# MK20D5 register map
File version: 1.6
Registers are 8-bit, read-write, reset 0x0 unless marked. A register's access mark holds for its fields unless they carry their own. Offsets are from the block's base; [hi:lo] are bit positions; lines under a group give offsets from that group.

## SystemControl — System Control Registers
Base 0xE000E000; register names take the prefix SCB_
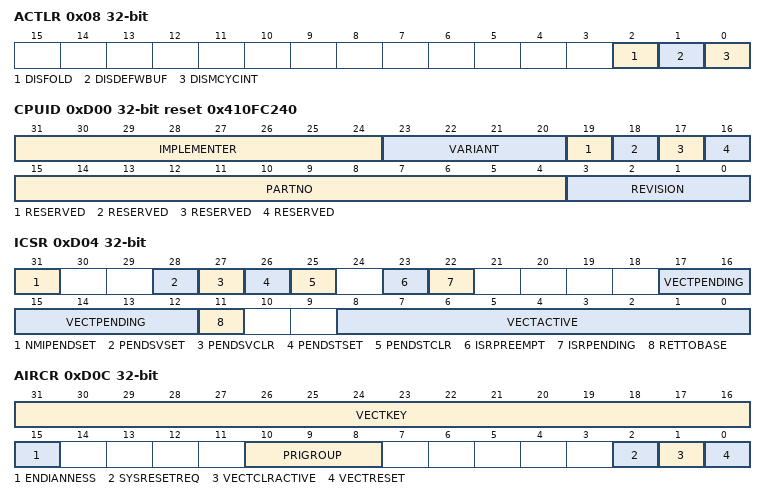
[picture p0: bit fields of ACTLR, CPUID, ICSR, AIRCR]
0x08 ACTLR 32-bit access per field — Auxiliary Control Register,
  [2] DISFOLD rw — Disables folding of IT instructions.
  [1] DISDEFWBUF rw — Disables write buffer use during default memory map accesses.
  [0] DISMCYCINT rw — Disables interruption of multi-cycle instructions.
0xD00 CPUID 32-bit ro reset 0x410FC240 — CPUID Base Register
  [31:24] IMPLEMENTER — Implementer code
  [23:20] VARIANT — Indicates processor revision: 0x2 = Revision 2
  [19] RESERVED — (Constant) Reads as 1
  [18] RESERVED — (Constant) Reads as 1
  [17] RESERVED — (Constant) Reads as 1
  [16] RESERVED — (Constant) Reads as 1
  [15:4] PARTNO — Indicates part number
  [3:0] REVISION — Indicates patch release: 0x0 = Patch 0
0xD04 ICSR 32-bit access per field — Interrupt Control and State Register
  [31] NMIPENDSET rw
    0=write: no effect; read: NMI exception is not pending; 1=write: changes NMI exception state to pending; read: NMI exception is pending
  [28] PENDSVSET rw
    0=write: no effect; read: PendSV exception is not pending; 1=write: changes PendSV exception state to pending; read: PendSV exception is pending
  [27] PENDSVCLR wo
    0=no effect; 1=removes the pending state from the PendSV exception
  [26] PENDSTSET rw
    0=write: no effect; read: SysTick exception is not pending; 1=write: changes SysTick exception state to pending; read: SysTick exception is pending
  [25] PENDSTCLR wo
    0=no effect; 1=removes the pending state from the SysTick exception
  [23] ISRPREEMPT ro
    0=Will not service; 1=Will service a pending exception
  [22] ISRPENDING ro
  [17:12] VECTPENDING ro — Exception number of the highest priority pending enabled exception
  [11] RETTOBASE ro
    0=there are preempted active exceptions to execute; 1=there are no active exceptions, or the currently-executing exception is the only active exception
  [8:0] VECTACTIVE ro — Active exception number
0xD08 VTOR 32-bit — Vector Table Offset Register
  [31:7] TBLOFF — Vector table base offset
0xD0C AIRCR 32-bit access per field — Application Interrupt and Reset Control Register
  [31:16] VECTKEY rw — Register key
  [15] ENDIANNESS ro
    0=Little-endian; 1=Big-endian
  [10:8] PRIGROUP rw — Interrupt priority grouping field. This field determines the split of group priority from subpriority.
  [2] SYSRESETREQ wo
    0=no system reset request; 1=asserts a signal to the outer system that requests a reset
  [1] VECTCLRACTIVE wo
  [0] VECTRESET wo
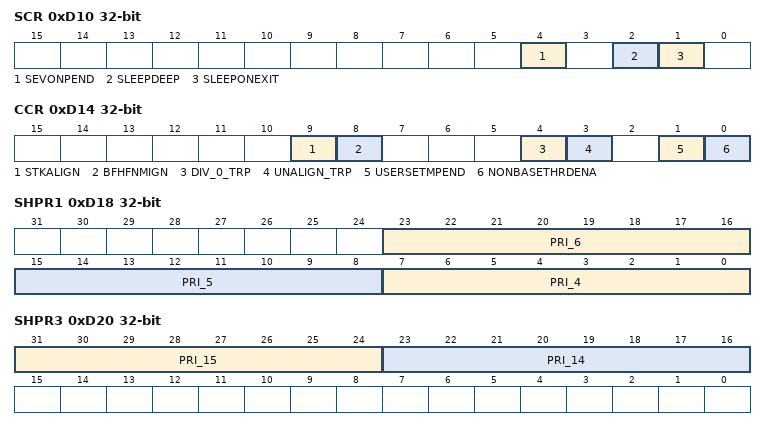
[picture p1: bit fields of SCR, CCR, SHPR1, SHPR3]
0xD10 SCR 32-bit access per field — System Control Register
  [4] SEVONPEND rw
    0=only enabled interrupts or events can wakeup the processor, disabled interrupts are excluded; 1=enabled events and all interrupts, including disabled interrupts, can wakeup the processor
  [2] SLEEPDEEP rw
    0=sleep; 1=deep sleep
  [1] SLEEPONEXIT rw
    0=o not sleep when returning to Thread mode; 1=enter sleep, or deep sleep, on return from an ISR
0xD14 CCR 32-bit access per field — Configuration and Control Register
  [9] STKALIGN rw — Indicates stack alignment on exception entry
    0=4-byte aligned; 1=8-byte aligned
  [8] BFHFNMIGN rw — Enables handlers with priority -1 or -2 to ignore data BusFaults caused by load and store instructions.
    0=data bus faults caused by load and store instructions cause a lock-up; 1=handlers running at priority -1 and -2 ignore data bus faults caused by load and store instructions
  [4] DIV_0_TRP rw — Enables faulting or halting when the processor executes an SDIV or UDIV instruction with a divisor of 0
    0=do not trap divide by 0; 1=trap divide by 0
  [3] UNALIGN_TRP rw — Enables unaligned access traps
    0=do not trap unaligned halfword and word accesses; 1=trap unaligned halfword and word accesses
  [1] USERSETMPEND rw — Enables unprivileged software access to the STIR
    0=disable; 1=enable
  [0] NONBASETHRDENA rw
    0=processor can enter Thread mode only when no exception is active; 1=processor can enter Thread mode from any level under the control of an EXC_RETURN value
0xD18 SHPR1 32-bit access per field — System Handler Priority Register 1
  [23:16] PRI_6 rw — Priority of system handler 6, UsageFault
  [15:8] PRI_5 rw — Priority of system handler 5, BusFault
  [7:0] PRI_4 rw — Priority of system handler 4, MemManage
0xD1C SHPR2 32-bit access per field — System Handler Priority Register 2
  [31:24] PRI_11 rw — Priority of system handler 11, SVCall
0xD20 SHPR3 32-bit access per field — System Handler Priority Register 3
  [31:24] PRI_15 rw — Priority of system handler 15, SysTick exception
  [23:16] PRI_14 rw — Priority of system handler 14, PendSV
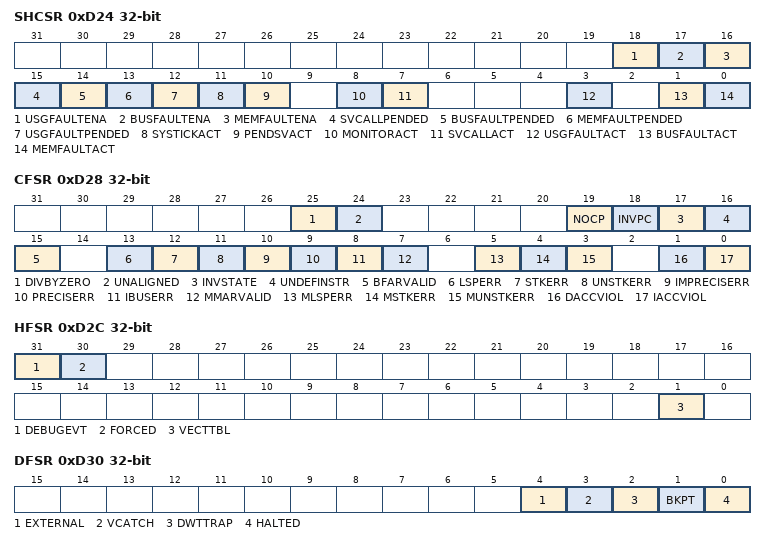
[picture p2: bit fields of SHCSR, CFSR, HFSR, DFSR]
0xD24 SHCSR 32-bit — System Handler Control and State Register
  [18] USGFAULTENA
    0=disable the exception; 1=enable the exception
  [17] BUSFAULTENA
    0=disable the exception; 1=enable the exception
  [16] MEMFAULTENA
    0=disable the exception; 1=enable the exception
  [15] SVCALLPENDED
    0=exception is not pending; 1=exception is pending
  [14] BUSFAULTPENDED
    0=exception is not pending; 1=exception is pending
  [13] MEMFAULTPENDED
    0=exception is not pending; 1=exception is pending
  [12] USGFAULTPENDED
    0=exception is not pending; 1=exception is pending
  [11] SYSTICKACT
    0=exception is not active; 1=exception is active
  [10] PENDSVACT
    0=exception is not active; 1=exception is active
  [8] MONITORACT
    0=exception is not active; 1=exception is active
  [7] SVCALLACT
    0=exception is not active; 1=exception is active
  [3] USGFAULTACT
    0=exception is not active; 1=exception is active
  [1] BUSFAULTACT
    0=exception is not active; 1=exception is active
  [0] MEMFAULTACT
    0=exception is not active; 1=exception is active
0xD28 CFSR 32-bit access per field — Configurable Fault Status Registers
  [25] DIVBYZERO rw
    0=no divide by zero fault, or divide by zero trapping not enabled; 1=the processor has executed an SDIV or UDIV instruction with a divisor of 0
  [24] UNALIGNED rw
    0=no unaligned access fault, or unaligned access trapping not enabled; 1=the processor has made an unaligned memory access
  [19] NOCP rw
    0=no UsageFault caused by attempting to access a coprocessor; 1=the processor has attempted to access a coprocessor
  [18] INVPC rw
    0=no invalid PC load UsageFault; 1=the processor has attempted an illegal load of EXC_RETURN to the PC
  [17] INVSTATE rw
    0=no invalid state UsageFault; 1=the processor has attempted to execute an instruction that makes illegal use of the EPSR
  [16] UNDEFINSTR rw
    0=no undefined instruction UsageFault; 1=the processor has attempted to execute an undefined instruction
  [15] BFARVALID rw
    0=value in BFAR is not a valid fault address; 1=BFAR holds a valid fault address
  [13] LSPERR rw
    0=No bus fault occurred during floating-point lazy state preservation; 1=A bus fault occurred during floating-point lazy state preservation
  [12] STKERR rw
    0=no stacking fault; 1=stacking for an exception entry has caused one or more BusFaults
  [11] UNSTKERR rw
    0=no unstacking fault; 1=unstack for an exception return has caused one or more BusFaults
  [10] IMPRECISERR rw
    0=no imprecise data bus error; 1=a data bus error has occurred, but the return address in the stack frame is not related to the instruction that caused the error
  [9] PRECISERR rw
    0=no precise data bus error; 1=a data bus error has occurred, and the PC value stacked for the exception return points to the instruction that caused the fault
  [8] IBUSERR rw
    0=no instruction bus error; 1=instruction bus error
  [7] MMARVALID rw
    0=value in MMAR is not a valid fault address; 1=MMAR holds a valid fault address
  [5] MLSPERR rw
    0=No MemManage fault occurred during floating-point lazy state preservation; 1=A MemManage fault occurred during floating-point lazy state preservation
  [4] MSTKERR rw
    0=no stacking fault; 1=stacking for an exception entry has caused one or more access violations
  [3] MUNSTKERR rw
    0=no unstacking fault; 1=unstack for an exception return has caused one or more access violations
  [1] DACCVIOL rw
    0=no data access violation fault; 1=the processor attempted a load or store at a location that does not permit the operation
  [0] IACCVIOL rw
    0=no instruction access violation fault; 1=the processor attempted an instruction fetch from a location that does not permit execution
0xD2C HFSR 32-bit access per field — HardFault Status register
  [31] DEBUGEVT rw
  [30] FORCED rw
    0=no forced HardFault; 1=forced HardFault
  [1] VECTTBL rw
    0=no BusFault on vector table read; 1=BusFault on vector table read
0xD30 DFSR 32-bit — Debug Fault Status Register
  [4] EXTERNAL
    0=No EDBGRQ debug event; 1=EDBGRQ debug event
  [3] VCATCH
    0=No Vector catch triggered; 1=Vector catch triggered
  [2] DWTTRAP
    0=No current debug events generated by the DWT; 1=At least one current debug event generated by the DWT
  [1] BKPT
    0=No current breakpoint debug event; 1=At least one current breakpoint debug event
  [0] HALTED
    0=No active halt request debug event; 1=Halt request debug event active
0xD34 MMFAR 32-bit — MemManage Address Register
  [31:0] ADDRESS — Address of MemManage fault location
0xD38 BFAR 32-bit — BusFault Address Register
  [31:0] ADDRESS — Address of the BusFault location
0xD3C AFSR 32-bit — Auxiliary Fault Status Register
  [31:0] AUXFAULT — Latched version of the AUXFAULT inputs
